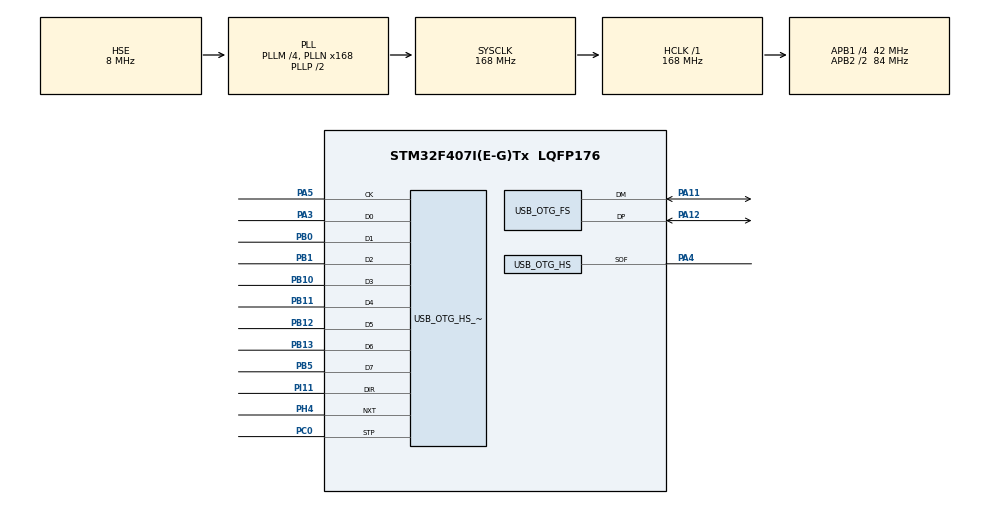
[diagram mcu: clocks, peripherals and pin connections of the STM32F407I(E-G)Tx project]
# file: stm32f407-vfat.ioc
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Mcu.Family=STM32F4
Mcu.Name=STM32F407I(E-G)Tx
Mcu.Package=LQFP176
NVIC.OTG_HS_IRQn=true\:5\:0\:true\:false\:true\:true\:true\:true
NVIC.PriorityGroup=NVIC_PRIORITYGROUP_4
NVIC.TIM3_IRQn=true\:4\:0\:true\:false\:true\:true\:true\:true
NVIC.TIM7_IRQn=true\:3\:0\:true\:false\:true\:false\:true\:true
NVIC.TimeBase=TIM7_IRQn
NVIC.TimeBaseIP=TIM7
PA11.Mode=Device_Only
PA11.Signal=USB_OTG_FS_DM
PA12.Mode=Device_Only
PA12.Signal=USB_OTG_FS_DP
PA13.Mode=JTAG_4_pins
PA13.Signal=SYS_JTMS-SWDIO
PA14.Mode=JTAG_4_pins
PA14.Signal=SYS_JTCK-SWCLK
PA15.Mode=JTAG_4_pins
PA15.Signal=SYS_JTDI
PA3.Mode=Host_HS
PA3.Signal=USB_OTG_HS_ULPI_D0
PA4.Mode=Activate_SOF_FS
PA4.Signal=USB_OTG_HS_SOF
PA5.Mode=Host_HS
PA5.Signal=USB_OTG_HS_ULPI_CK
PB0.Mode=Host_HS
PB0.Signal=USB_OTG_HS_ULPI_D1
PB1.Mode=Host_HS
PB1.Signal=USB_OTG_HS_ULPI_D2
PB10.Mode=Host_HS
PB10.Signal=USB_OTG_HS_ULPI_D3
PB11.Mode=Host_HS
PB11.Signal=USB_OTG_HS_ULPI_D4
PB12.Mode=Host_HS
PB12.Signal=USB_OTG_HS_ULPI_D5
PB13.Mode=Host_HS
PB13.Signal=USB_OTG_HS_ULPI_D6
PB3.Mode=JTAG_4_pins
PB3.Signal=SYS_JTDO-SWO
PB5.Mode=Host_HS
PB5.Signal=USB_OTG_HS_ULPI_D7
PC0.Mode=Host_HS
PC0.Signal=USB_OTG_HS_ULPI_STP
PC14-OSC32_IN.Mode=LSE-External-Oscillator
PC14-OSC32_IN.Signal=RCC_OSC32_IN
PC15-OSC32_OUT.Mode=LSE-External-Oscillator
PC15-OSC32_OUT.Signal=RCC_OSC32_OUT
PH0-OSC_IN.Mode=HSE-External-Oscillator
PH0-OSC_IN.Signal=RCC_OSC_IN
PH1-OSC_OUT.Mode=HSE-External-Oscillator
PH1-OSC_OUT.Signal=RCC_OSC_OUT
PH4.Mode=Host_HS
PH4.Signal=USB_OTG_HS_ULPI_NXT
PI11.Mode=Host_HS
PI11.Signal=USB_OTG_HS_ULPI_DIR
ProjectManager.HeapSize=0x200
ProjectManager.StackSize=0x400
ProjectManager.TargetToolchain=STM32CubeIDE
RCC.48MHZClocksFreq_Value=48000000
RCC.AHBFreq_Value=168000000
RCC.APB1CLKDivider=RCC_HCLK_DIV4
RCC.APB1Freq_Value=42000000
RCC.APB1TimFreq_Value=84000000
RCC.APB2CLKDivider=RCC_HCLK_DIV2
RCC.APB2Freq_Value=84000000
RCC.APB2TimFreq_Value=168000000
RCC.CortexFreq_Value=168000000
RCC.HCLKFreq_Value=168000000
RCC.HSE_VALUE=8000000
RCC.HSI_VALUE=16000000
RCC.PLLM=4
RCC.PLLN=168
RCC.PLLQ=7
RCC.RCC_RTC_Clock_Source=RCC_RTCCLKSOURCE_LSE
RCC.RCC_RTC_Clock_SourceVirtual=RCC_RTCCLKSOURCE_LSE
RCC.SYSCLKFreq_VALUE=168000000
RCC.SYSCLKSource=RCC_SYSCLKSOURCE_PLLCLK
RCC.VCOOutputFreq_Value=336000000
STMicroelectronics.X-CUBE-AZRTOS-F4.1.1.0.UX_MAX_HCD=2
STMicroelectronics.X-CUBE-AZRTOS-F4.1.1.0_IsAnAzureRtosMw=true
TIM3.AutoReloadPreload=TIM_AUTORELOAD_PRELOAD_ENABLE
TIM3.ClockDivision=TIM_CLOCKDIVISION_DIV1
TIM3.Period=9
TIM3.Prescaler=8399
USB_HOST.SW_VBUS_DRIVE_HID_HS=true
USB_HOST.USBH_HandleTypeDef-HID_HS=hUsbHostHS
USB_HOST.VirtualModeHS=Hid
USB_OTG_FS.VirtualMode=Device_Only
USB_OTG_HS.VirtualMode-Host_HS=Host_HS
USB_OTG_HS.dma_enable-Host_HS=DISABLE
VP_RTC_VS_RTC_Activate.Mode=RTC_Enabled
VP_RTC_VS_RTC_Calendar.Mode=RTC_Calendar
VP_SYS_VS_tim7.Mode=TIM7
VP_TIM3_VS_ClockSourceITR.Mode=TriggerSource_ITR0
VP_USB_HOST_VS_USB_HOST_HID_HS.Mode=HID_HS
board=custom

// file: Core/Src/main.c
/* USER CODE BEGIN Header */
/**
  ******************************************************************************
  * @file           : main.c
  * @brief          : Main program body
  ******************************************************************************
  * @attention
  *
  * Copyright (c) 2026 STMicroelectronics.
  * All rights reserved.
  *
  * This software is licensed under terms that can be found in the LICENSE file
  * in the root directory of this software component.
  * If no LICENSE file comes with this software, it is provided AS-IS.
  *
  ******************************************************************************
  */
/* USER CODE END Header */
#include "main.h"
#include "rtc.h"
#include "tim.h"
#include "usb_host.h"
#include "usb_otg_fs.h"
#include "gpio.h"

/* USER CODE BEGIN Includes */
#include "startup.h"
/* USER CODE END Includes */

void SystemClock_Config(void);
void MX_USB_HOST_Process(void);

int main(void)
{

  /* MCU Configuration--------------------------------------------------------*/

  /* Reset of all peripherals, Initializes the Flash interface and the Systick. */
  HAL_Init();

  /* Configure the system clock */
  SystemClock_Config();

  /* USER CODE BEGIN SysInit */
  initialize();
  /* USER CODE END SysInit */

  /* Initialize all configured peripherals */
  MX_GPIO_Init();
  MX_RTC_Init();
  MX_USB_HOST_Init();
  MX_TIM3_Init();
  /* USER CODE BEGIN 2 */
  setup();
  /* USER CODE END 2 */

  /* Infinite loop */
  /* USER CODE BEGIN WHILE */
  while (1)
  {
	loop();
	continue;
    /* USER CODE END WHILE */
    MX_USB_HOST_Process();

  }
}

void SystemClock_Config(void)
{
  RCC_OscInitTypeDef RCC_OscInitStruct = {0};
  RCC_ClkInitTypeDef RCC_ClkInitStruct = {0};

  /** Configure the main internal regulator output voltage
  */
  __HAL_RCC_PWR_CLK_ENABLE();
  __HAL_PWR_VOLTAGESCALING_CONFIG(PWR_REGULATOR_VOLTAGE_SCALE1);

  /** Initializes the RCC Oscillators according to the specified parameters
  * in the RCC_OscInitTypeDef structure.
  */
  RCC_OscInitStruct.OscillatorType = RCC_OSCILLATORTYPE_HSE|RCC_OSCILLATORTYPE_LSE;
  RCC_OscInitStruct.HSEState = RCC_HSE_ON;
  RCC_OscInitStruct.LSEState = RCC_LSE_ON;
  RCC_OscInitStruct.PLL.PLLState = RCC_PLL_ON;
  RCC_OscInitStruct.PLL.PLLSource = RCC_PLLSOURCE_HSE;
  RCC_OscInitStruct.PLL.PLLM = 4;
  RCC_OscInitStruct.PLL.PLLN = 168;
  RCC_OscInitStruct.PLL.PLLP = RCC_PLLP_DIV2;
  RCC_OscInitStruct.PLL.PLLQ = 7;
  if (HAL_RCC_OscConfig(&RCC_OscInitStruct) != HAL_OK)
  {
    Error_Handler();
  }

  /** Initializes the CPU, AHB and APB buses clocks
  */
  RCC_ClkInitStruct.ClockType = RCC_CLOCKTYPE_HCLK|RCC_CLOCKTYPE_SYSCLK
                              |RCC_CLOCKTYPE_PCLK1|RCC_CLOCKTYPE_PCLK2;
  RCC_ClkInitStruct.SYSCLKSource = RCC_SYSCLKSOURCE_PLLCLK;
  RCC_ClkInitStruct.AHBCLKDivider = RCC_SYSCLK_DIV1;
  RCC_ClkInitStruct.APB1CLKDivider = RCC_HCLK_DIV4;
  RCC_ClkInitStruct.APB2CLKDivider = RCC_HCLK_DIV2;

  if (HAL_RCC_ClockConfig(&RCC_ClkInitStruct, FLASH_LATENCY_5) != HAL_OK)
  {
    Error_Handler();
  }
}

void HAL_TIM_PeriodElapsedCallback(TIM_HandleTypeDef *htim)
{
  if (htim->Instance == TIM7)
  {
    HAL_IncTick();
  }
  /* USER CODE BEGIN Callback 1 */
  if (htim->Instance == TIM3)
  {
	  MX_USB_HOST_Process();
  }
  /* USER CODE END Callback 1 */
}

void Error_Handler(void)
{
  __disable_irq();
  while (1)
  {
  }
}
